# LAN9255ZMX020 register map
Vendor: Microchip
Registers are 32-bit, read-write, reset 0x0 unless marked. A register's access mark holds for its fields unless they carry their own. Addresses are absolute, and some are shared; only a register's first bit layout is shown; [hi:lo] are bit positions; {n}, {i} and the like mark numbered series; 'fields as' and 'values as' point back to an identical list.

## ITM
{0xE0000000+4i} PORT{i} wo reset not defined (i=0..31)
  [31:0] PORT
0xE0000E00 TER reset not defined
0xE0000E40 TPR reset not defined
  [3:0] PRIVMASK
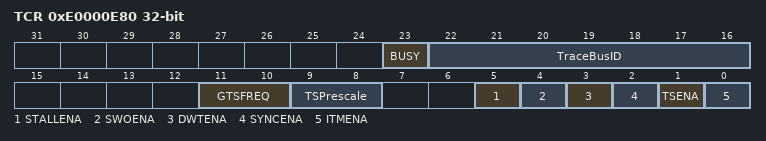
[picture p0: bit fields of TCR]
0xE0000E80 TCR reset not defined
  [23] BUSY, [22:16] TraceBusID, [11:10] GTSFREQ, [9:8] TSPrescale, [5] STALLENA, [4] SWOENA, [3] DWTENA, [2] SYNCENA, [1] TSENA, [0] ITMENA
0xE0000EF8 IWR wo reset not defined
  [0] ATVALIDM
0xE0000EFC IRR ro reset not defined
  [0] ATREADYM

## DWT
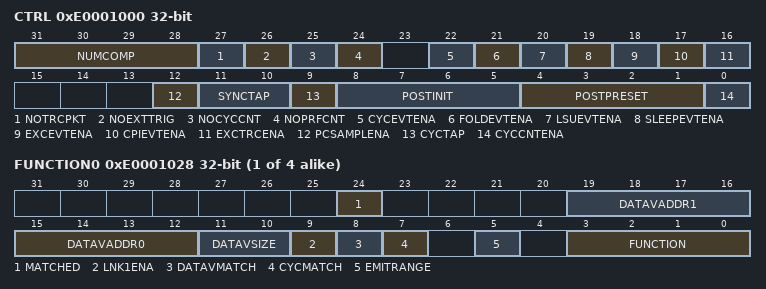
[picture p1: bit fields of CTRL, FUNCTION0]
0xE0001000 CTRL reset not defined
  [31:28] NUMCOMP, [27] NOTRCPKT, [26] NOEXTTRIG, [25] NOCYCCNT, [24] NOPRFCNT, [22] CYCEVTENA, [21] FOLDEVTENA, [20] LSUEVTENA, [19] SLEEPEVTENA, [18] EXCEVTENA, [17] CPIEVTENA, [16] EXCTRCENA, [12] PCSAMPLENA, [11:10] SYNCTAP, [9] CYCTAP, [8:5] POSTINIT, [4:1] POSTPRESET, [0] CYCCNTENA
0xE0001004 CYCCNT reset not defined
0xE0001008 CPICNT reset not defined
  [7:0] CPICNT
0xE000100C EXCCNT reset not defined
  [7:0] EXCCNT
0xE0001010 SLEEPCNT reset not defined
  [7:0] SLEEPCNT
0xE0001014 LSUCNT reset not defined
  [7:0] LSUCNT
0xE0001018 FOLDCNT reset not defined
  [7:0] FOLDCNT
0xE000101C PCSR ro reset not defined
{0xE0001020+0x10*i} COMP{i} reset not defined (i=0..3)
{0xE0001024+0x10*i} MASK{i} reset not defined (i=0..3)
  [4:0] MASK
{0xE0001028+0x10*i} FUNCTION{i} reset not defined (i=0..3)
  [24] MATCHED, [19:16] DATAVADDR1, [15:12] DATAVADDR0, [11:10] DATAVSIZE, [9] LNK1ENA, [8] DATAVMATCH, [7] CYCMATCH, [5] EMITRANGE, [3:0] FUNCTION

## SFR
0xE000E004 ICTR ro reset not defined — Interrupt Controller Type Register (power-on value xxxxxxxxxxxxxxxxxxxxxxxxxxxxxxxx)
  [3:0] INTLINESNUM — Number of interrupt lines supported by NVIC in granularities of 32.

## SysTick
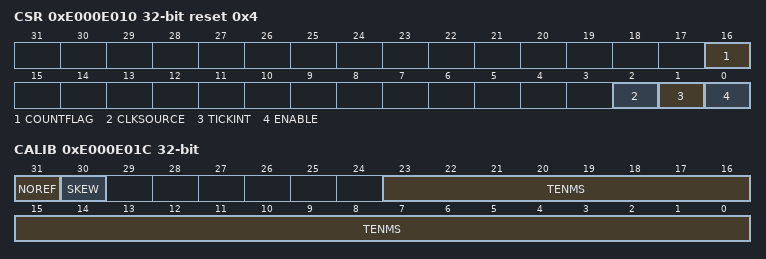
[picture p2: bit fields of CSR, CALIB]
0xE000E010 CSR reset 0x4
  [16] COUNTFLAG — Timer counted to 0 since last read of register
  [2] CLKSOURCE — Clock Source 0=external, 1=processor
    0=External clock; 1=Processor clock
  [1] TICKINT — SysTick Exception Request Enable
    0=Counting down to 0 does not assert the SysTick exception request; 1=Counting down to 0 asserts the SysTick exception request
  [0] ENABLE — SysTick Counter Enable
    0=Counter disabled; 1=Counter enabled
0xE000E014 RVR reset not defined
  [23:0] RELOAD — Value to load into the SysTick Current Value Register when the counter reaches 0
0xE000E018 CVR reset not defined
  [23:0] CURRENT — Current value at the time the register is accessed
0xE000E01C CALIB ro
  [31] NOREF — No Separate Reference Clock
    0=The reference clock is provided; 1=The reference clock is not provided
  [30] SKEW — TENMS is rounded from non-integer ratio
    0=10ms calibration value is exact; 1=10ms calibration value is inexact, because of the clock frequency
  [23:0] TENMS — Reload value to use for 10ms timing

## NVIC
{0xE000E100+4i} ISER{i} (i=0..4)
  [31:0] SETENA — Interrupt set enable bits
{0xE000E180+4i} ICER{i} (i=0..4)
  [31:0] CLRENA — Interrupt clear-enable bits
{0xE000E200+4i} ISPR{i} (i=0..4)
  [31:0] SETPEND — Interrupt set-pending bits
{0xE000E280+4i} ICPR{i} (i=0..4)
  [31:0] CLRPEND — Interrupt clear-pending bits
{0xE000E300+4i} IABR{i} (i=0..4)
  [31:0] ACTIVE — Interrupt active bits
{0xE000E400+i} IP{i} 8-bit (i=0..34)
  [2:0] PRI0 — Priority of interrupt n
0xE000EF00 STIR wo reset not defined
  [8:0] INTID — Interrupt ID to trigger

## MPU
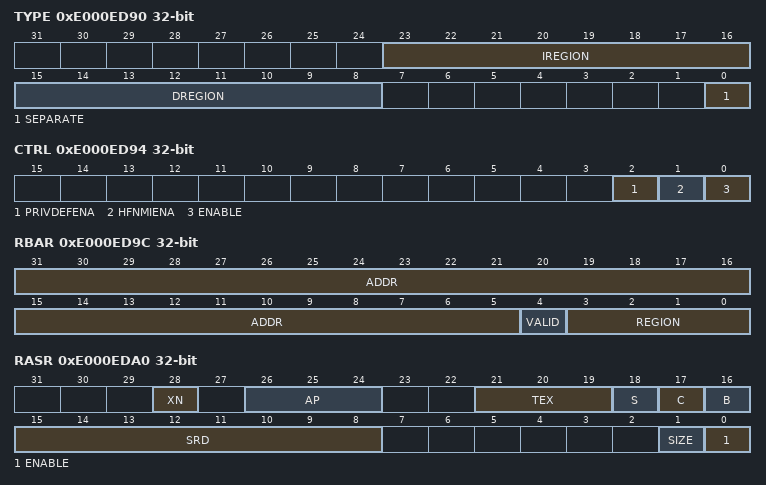
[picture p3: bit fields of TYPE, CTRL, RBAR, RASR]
0xE000ED90 TYPE ro reset not defined
  [23:16] IREGION — Number of Instruction Regions
  [15:8] DREGION — Number of Data Regions
  [0] SEPARATE — Separate instruction and Data Memory MapsRegions
0xE000ED94 CTRL reset not defined
  [2] PRIVDEFENA — Enables privileged software access to default memory map
  [1] HFNMIENA — Enable Hard Fault and NMI handlers
  [0] ENABLE — MPU Enable
0xE000ED98 RNR reset not defined
  [7:0] REGION — Region referenced by RBAR and RASR
0xE000ED9C RBAR reset not defined
  [31:5] ADDR — Region base address
  [4] VALID — Region number valid
  [3:0] REGION — Region number
0xE000EDA0 RASR reset not defined
  [28] XN — Execute Never Attribute
  [26:24] AP — Access Permission
  [21:19] TEX — TEX bit
  [18] S — Shareable bit
  [17] C — Cacheable bit
  [16] B — Bufferable bit
  [15:8] SRD — Sub-region disable
  [1] SIZE — Region Size
  [0] ENABLE — Region Enable
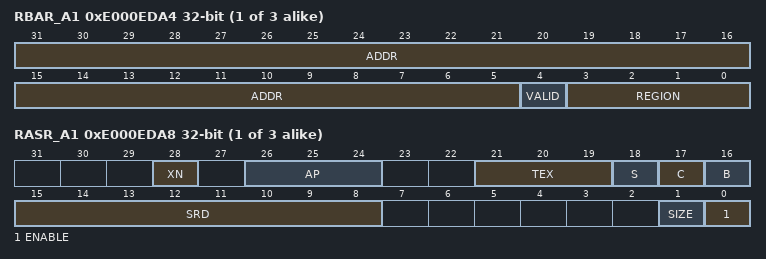
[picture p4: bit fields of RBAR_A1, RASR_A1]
{0xE000ED9C+8i} RBAR_A{i} reset not defined (i=1..3)
  fields as RBAR
{0xE000EDA0+8i} RASR_A{i} reset not defined (i=1..3)
  fields as RASR
